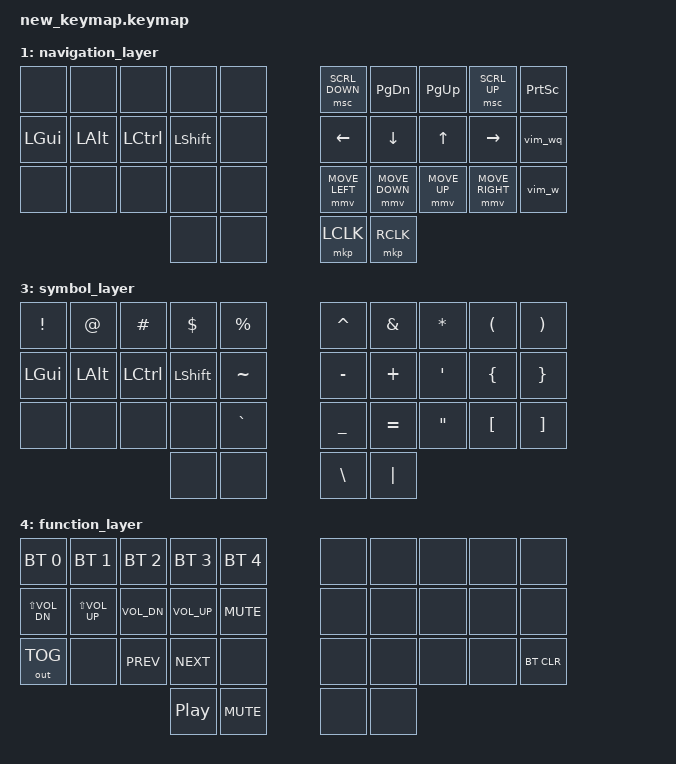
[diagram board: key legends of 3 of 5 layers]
#include <behaviors.dtsi>
#include <dt-bindings/zmk/keys.h>
#include <dt-bindings/zmk/bt.h>
#include <dt-bindings/zmk/outputs.h>
#include <dt-bindings/zmk/pointing.h>

// Define layers
#define NAV 1
#define NUM  2
#define SYM 3
#define FUN 4

// Home row mods macro
#define HRML(k1,k2,k3,k4) &hml LGUI k1  &hml LALT k2  &hml LCTRL k3  &hml LSHFT k4
#define HRMR(k1,k2,k3,k4) &hmr RSHFT k1  &hmr RCTRL k2  &hmr RALT k3  &hmr RGUI k4

#define ht_tt 200
#define ht_qt 125
#define ht_rpi 100
#define ZMK_POINTING_DEFAULT_MOVE_VAL 800
#define ZMK_POINTING_DEFAULT_SCRL_VAL 10


/ {
    behaviors {
        lt: layer_tap {
            compatible = "zmk,behavior-hold-tap";
            #binding-cells = <2>;
            flavor = "tap-preferred";
            tapping-term-ms = <180>;
            bindings = <&mo>, <&kp>;
            quick-tap-ms = <150>;
        };

        hml: home_row_mod_left {
            compatible = "zmk,behavior-hold-tap";
            #binding-cells = <2>;
            flavor = "tap-preferred";
            require-prior-idle-ms = <ht_rpi>;
            tapping-term-ms = <ht_tt>;
            quick-tap-ms = <ht_qt>;
            bindings = <&kp>, <&kp>;
            hold-trigger-on-release;
        };
        hmr: home_row_mod_right {
            compatible = "zmk,behavior-hold-tap";
            #binding-cells = <2>;
            flavor = "tap-preferred";
            require-prior-idle-ms = <ht_rpi>;
            tapping-term-ms = <ht_tt>;
            quick-tap-ms = <ht_qt>;
            bindings = <&kp>, <&kp>;
            hold-trigger-on-release;
        };
        //I used for prior version of mod tap
        ht: hold_tap {
            compatible = "zmk,behavior-hold-tap";
            #binding-cells = <2>;
            flavor = "tap-preferred";
            tapping-term-ms = <ht_tt>;
            quick-tap-ms = <ht_qt>;
            require-prior-idle-ms = <ht_rpi>;
            bindings = <&kp>, <&kp>;
        };
        sk: sticky_key {
            release-after-ms = <2000>;
            quick-release;
            ignore-modifiers;
        };
    };
    macros {
        vim_wq: vim_wq {
            compatible = "zmk,behavior-macro";
            wait-ms = <40>;
            tap-ms = <40>;
            #binding-cells = <0>;
            bindings = 
                  <&kp COLON>
                , <&kp W>
                , <&kp Q>
                , <&kp ENTER>
                ;
        };
        vim_w: vim_w{
            compatible = "zmk,behavior-macro";
            wait-ms = <40>;
            tap-ms = <40>;
            #binding-cells = <0>;
            bindings = 
                  <&kp COLON>
                , <&kp W>
                , <&kp ENTER>
                ;
        };
        vim_q: vim_q{
            compatible = "zmk,behavior-macro";
            wait-ms = <40>;
            tap-ms = <40>;
            #binding-cells = <0>;
            bindings = 
                  <&kp COLON>
                , <&kp Q>
                , <&kp ENTER>
                ;
        };
    };
    combos {
        compatible = "zmk,combos";
        combo_esc {
            timeout-ms = <60>;
            key-positions = <12 17>;
            bindings = <&kp ESC>;
            layers = <0>;
            require-prior-idle-ms = <100>;
        };
        combo_capword{
            timeout-ms = <60>;
            key-positions = <31 32>;
            bindings = <&caps_word>;
            layers = <0>;
            require-prior-idle-ms = <100>;
        };
        combo_caplock {
            timeout-ms = <40>;
            key-positions = <11 12>;
            bindings = <&kp CAPS>;
            layers = <0>;
            require-prior-idle-ms = <100>;
        };
        combo_delete{
            timeout-ms = <40>;
            key-positions = <7 8>;
            bindings = <&kp DEL>;
            layers = <0>;
            require-prior-idle-ms = <100>;
        };
    };

    keymap {
        compatible = "zmk,keymap";
        default_layer {
            bindings = <
                //╭──────────┬──────────┬──────────┬──────────┬──────────╮   ╭──────────┬──────────┬──────────┬──────────┬──────────╮
                //│  Q       │  W       │  E       │  R       │  T       │   │  Y       │  U       │  I       │  O       │   P      │
                    &kp Q      &kp W      &kp E      &kp R      &kp T          &kp Y      &kp U     &kp I        &kp O      &kp P 
                //├──────────┼──────────┼──────────┼──────────┼──────────┤   ├──────────┼──────────┼──────────┼──────────┼──────────┤
                //│  A       │  S       │  D       │  F       │  G       │   │  H       │  J       │  K       │  L       │  ; :     │
                    HRML( A,     S,        D,           F)      &kp G         &lt FUN H  HRMR(J,      K,        L,         SEMI)
                //├──────────┼──────────┼──────────┼──────────┼──────────┤   ├──────────┼──────────┼──────────┼──────────┼──────────┤
                //│  Z       │  X       │  C       │  V       │  B       │   │  N       │  M       │ , <      │ . >      │ / ?      │
                    &kp Z       &kp X      &kp C      &kp V      &kp B          &kp N      &kp M      &kp COMMA  &kp DOT    &kp FSLH
                //╰──────────┴──────────┴──────────┼──────────┼──────────┤   ├──────────┼──────────┼──────────┴──────────┴──────────╯
                                                   &lt NAV TAB &lt SYM BSPC   &kp SPACE &lt NUM ENTER
                //                                 ╰──────────┴──────────╯   ╰──────────┴──────────╯
            >;
        };
         
        navigation_layer {
            bindings = <
                //╭──────────┬──────────┬──────────┬──────────┬──────────╮   ╭──────────┬──────────┬──────────┬──────────┬──────────╮
                //│          │          │          │          │          │   │  HOME    │  PG_DN   │ PG_UP    │  S_UP    │   PTS    │
                    &none      &none      &none      &none       &none        &msc SCRL_DOWN &kp PG_DN &kp PG_UP &msc SCRL_UP &kp PSCRN
                //├──────────┼──────────┼──────────┼──────────┼──────────┤   ├──────────┼──────────┼──────────┼──────────┼──────────┤
                //│          │          │          │          │          │   │   left   │  down    │   up     │  right   │          │
                    &kp LGUI   &kp LALT   &kp LCTRL  &kp LSHFT  &none          &kp LEFT   &kp DOWN   &kp UP     &kp RIGHT   &vim_wq
                //├──────────┼──────────┼──────────┼──────────┼──────────┤   ├──────────┼──────────┼──────────┼──────────┼──────────┤
                //│          │          │          │          │          │   │ m left   │ m down   │  m up    │ m  right │  ENTER   │
                     &none      &none      &none      &none       &none  &mmv MOVE_LEFT &mmv MOVE_DOWN &mmv MOVE_UP &mmv MOVE_RIGHT  &vim_w
                //╰──────────┴──────────┴──────────┼──────────┼──────────┤   ├──────────┼──────────┼──────────┴──────────┴──────────╯
                                                      &none       &none        &mkp LCLK  &mkp RCLK
            //                                     ╰──────────┴──────────╯   ╰──────────┴──────────╯
            >;
        };       
        
        number_layer {
            bindings = <
                //╭──────────┬──────────┬──────────┬──────────┬──────────╮   ╭──────────┬──────────┬──────────┬──────────┬──────────╮
                //│    1     │    2     │    3     │    4     │    5     │   │    6     │    7     │    8     │   9      │    0     │
                    &kp N1     &kp N2     &kp N3      &kp N4     &kp N5         &kp N6     &kp N7     &kp N8     &kp N9     &kp  N0
                //├──────────┼──────────┼──────────┼──────────┼──────────┤   ├──────────┼──────────┼──────────┼──────────┼──────────┤
                //│          │          │          │          │          │   │    -     │          │          │          │          │
                    &kp LGUI   &kp LALT   &kp LCTRL  &kp LSHFT   &none         &kp MINUS  HRMR(PLUS,   ASTRK ,      DOT,      FSLH)
                //├──────────┼──────────┼──────────┼──────────┼──────────┤   ├──────────┼──────────┼──────────┼──────────┼──────────┤
                //│    F1    │    F2    │    F3    │    F4    │    F5    │   │    F6    │   F7     │    F8    │   F9     │   F10    │
                    &kp F1      &kp F2     &kp F3     &kp F4     &kp F5         &kp F6      &kp F7     &kp F8     &kp F9     &kp F10
                //╰──────────┴──────────┴──────────┼──────────┼──────────┤   ├──────────┼──────────┼──────────┴──────────┴──────────╯
                                                      &none      &kp F11       &kp F12     &none
                //                                 ╰──────────┴──────────╯   ╰──────────┴──────────╯
            >;
        };
        symbol_layer {
            bindings = <
                //╭──────────┬──────────┬──────────┬──────────┬──────────╮   ╭──────────┬──────────┬──────────┬──────────┬──────────╮
                //│     !    │    @     │    #     │    $     │    %     │   │    ^     │    &     │     *    │    (     │    )     │
                    &kp EXCL   &kp AT     &kp HASH   &kp DLLR   &kp PRCNT      &kp CARET  &kp AMPS   &kp ASTRK  &kp LPAR   &kp RPAR
                //├──────────┼──────────┼──────────┼──────────┼──────────┤   ├──────────┼──────────┼──────────┼──────────┼──────────┤
                //│          │          │          │          │    ~     │   │    -     │    +     │    '     │    {     │    }     │
                   &kp LGUI    &kp LALT  &kp LCTRL   &kp LSHFT &kp TILDE       &kp MINUS  &kp PLUS    &kp SQT    &kp LBRC   &kp RBRC
                //├──────────┼──────────┼──────────┼──────────┼──────────┤   ├──────────┼──────────┼──────────┼──────────┼──────────┤
                //│          │          │          │          │    `     │   │    _     │    =     │    "     │    [     │    ]     │
                    &none      &none      &none      &none     &kp GRAVE       &kp UNDER   &kp EQUAL &kp DQT    &kp LBKT   &kp RBKT
                //╰──────────┴──────────┴──────────┼──────────┼──────────┤   ├──────────┼──────────┼──────────┴──────────┴──────────╯
                                                     &none      &none         &kp BSLH    &kp PIPE
                //                                 ╰──────────┴──────────╯   ╰──────────┴──────────╯
            >;
        };

        function_layer {
            bindings = <
                //╭──────────┬──────────┬──────────┬──────────┬──────────╮   ╭──────────┬──────────┬──────────┬──────────┬──────────╮
                //│          │          │          │          │          │   │          │          │          │          │          │
            &bt BT_SEL 0 &bt BT_SEL 1 &bt BT_SEL 2 &bt BT_SEL 3 &bt BT_SEL 4    &none      &none      &none      &none      &none
                //├──────────┼──────────┼──────────┼──────────┼──────────┤   ├──────────┼──────────┼──────────┼──────────┼──────────┤
                //│          │          │          │          │          │   │          │          │          │          │          │
         &kp LS(C_VOL_DN) &kp LS(C_VOL_UP) &kp C_VOL_DN &kp C_VOL_UP &kp C_MUTE &none      &none      &none      &none      &none
                //├──────────┼──────────┼──────────┼──────────┼──────────┤   ├──────────┼──────────┼──────────┼──────────┼──────────┤
                //│          │          │          │          │          │   │          │          │          │          │          │
                 &out OUT_TOG &none    &kp C_PREV  &kp C_NEXT    &none          &none      &none      &none      &none    &bt BT_CLR
                //╰──────────┴──────────┴──────────┼──────────┼──────────┤   ├──────────┼──────────┼──────────┴──────────┴──────────╯
                                                     &kp C_PP   &kp C_MUTE      &none      &none 
                //                                 ╰──────────┴──────────╯   ╰──────────┴──────────╯
            >;
        };
    };
};
